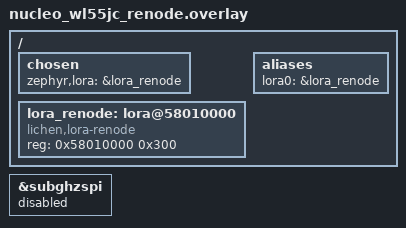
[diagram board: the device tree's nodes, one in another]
/*
 * Overlay for running nucleo_wl55jc in Renode with lichen-sim bridge.
 * Replaces the real SubGHz radio with our memory-mapped simulator driver.
 *
 * Usage:
 *   west build -b nucleo_wl55jc -- \
 *     -DEXTRA_DTC_OVERLAY_FILE=lichen/boards/renode/nucleo_wl55jc/nucleo_wl55jc_renode.overlay \
 *     -DEXTRA_CONF_FILE=lichen/boards/renode/nucleo_wl55jc/renode.conf
 */

/* Disable the real SubGHz radio */
&subghzspi {
	status = "disabled";
};

/ {
	chosen {
		zephyr,lora = &lora_renode;
	};

	/* Add our simulator radio at the SubGHz peripheral address */
	lora_renode: lora@58010000 {
		compatible = "lichen,lora-renode";
		reg = <0x58010000 0x300>;
		status = "okay";
	};

	aliases {
		lora0 = &lora_renode;
	};
};
